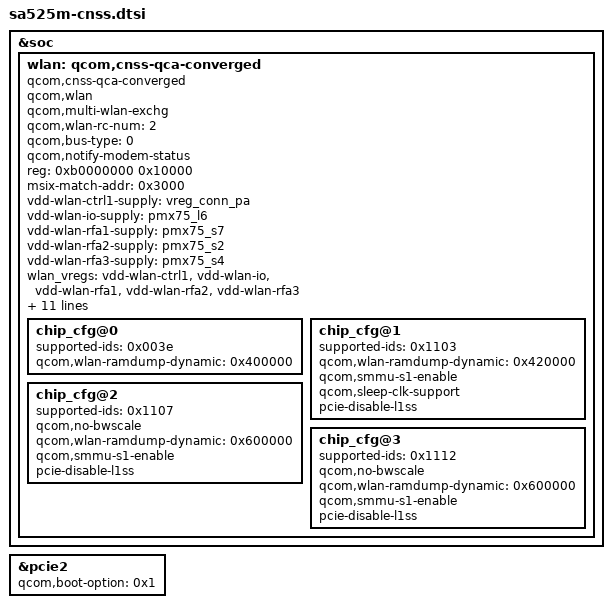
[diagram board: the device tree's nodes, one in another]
// SPDX-License-Identifier: BSD-3-Clause
//Copyright (c) Qualcomm Technologies, Inc. and/or its subsidiaries.
#include <dt-bindings/interconnect/qcom,sdxpinn.h>

&soc {
	wlan: qcom,cnss-qca-converged {
		compatible = "qcom,cnss-qca-converged";
		qcom,wlan;
		qcom,multi-wlan-exchg;
		qcom,wlan-rc-num = <2>;
		qcom,bus-type=<0>;
		qcom,notify-modem-status;

		reg = <0xb0000000 0x10000>;
		reg-names = "smmu_iova_ipa";

		msix-match-addr = <0x3000>;

		vdd-wlan-ctrl1-supply = <&vreg_conn_pa>;
		vdd-wlan-io-supply = <&pmx75_l6>;
		vdd-wlan-rfa1-supply = <&pmx75_s7>;
		vdd-wlan-rfa2-supply = <&pmx75_s2>;
		vdd-wlan-rfa3-supply = <&pmx75_s4>;

		wlan_vregs = "vdd-wlan-ctrl1", "vdd-wlan-io", "vdd-wlan-rfa1",
				"vdd-wlan-rfa2", "vdd-wlan-rfa3";
		qcom,vdd-wlan-ctrl1-config = <0 0 0 0 0>;
		qcom,vdd-wlan-io-config = <1800000 1800000 0 0 0>;
		qcom,vdd-wlan-rfa1-config = <1000000 1000000 0 0 0>;
		qcom,vdd-wlan-rfa2-config = <1300000 1300000 0 0 0>;
		qcom,vdd-wlan-rfa3-config = <1904000 1904000 450000 0 0>;
		wlan-en-gpio = <&pmk8550_gpios 3 0>;
		pinctrl-names = "wlan_en_active", "wlan_en_sleep";
		pinctrl-0 = <&wlan_en_active>;
		pinctrl-1 = <&wlan_en_sleep>;

		chip_cfg@0 {
			supported-ids = <0x003e>;
			qcom,wlan-ramdump-dynamic = <0x400000>;
		};

		chip_cfg@1 {
			supported-ids = <0x1103>;
			qcom,wlan-ramdump-dynamic = <0x420000>;
			qcom,smmu-s1-enable;
			qcom,sleep-clk-support;
			pcie-disable-l1ss;
		};

		chip_cfg@2 {
			supported-ids = <0x1107>;
			qcom,no-bwscale;
			qcom,wlan-ramdump-dynamic = <0x600000>;
			qcom,smmu-s1-enable;
			pcie-disable-l1ss;
		};

		chip_cfg@3 {
			supported-ids = <0x1112>;
			qcom,no-bwscale;
			qcom,wlan-ramdump-dynamic = <0x600000>;
			qcom,smmu-s1-enable;
			pcie-disable-l1ss;
		};
	};
};

&pcie2 {
	qcom,boot-option = <0x1>;
	status = "ok";
};
